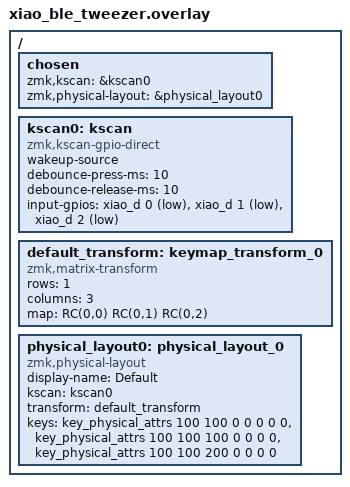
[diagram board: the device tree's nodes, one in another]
/*
 * SPDX-License-Identifier: MIT
 */

#include <dt-bindings/zmk/matrix_transform.h>
#include <physical_layouts.dtsi>
#include <zephyr/dt-bindings/gpio/gpio.h>

/ {
    chosen {
        zmk,kscan = &kscan0;
        zmk,physical-layout = &physical_layout0;
    };

    kscan0: kscan {
        compatible = "zmk,kscan-gpio-direct";
        wakeup-source;
        debounce-press-ms = <10>;
        debounce-release-ms = <10>;
        input-gpios
            = <&xiao_d 0 (GPIO_ACTIVE_LOW | GPIO_PULL_UP)>
            , <&xiao_d 1 (GPIO_ACTIVE_LOW | GPIO_PULL_UP)>
            , <&xiao_d 2 (GPIO_ACTIVE_LOW | GPIO_PULL_UP)>
            ;
    };

    default_transform: keymap_transform_0 {
        compatible = "zmk,matrix-transform";
        rows = <1>;
        columns = <3>;
        map = <RC(0,0) RC(0,1) RC(0,2)>;
    };

    physical_layout0: physical_layout_0 {
        compatible = "zmk,physical-layout";
        display-name = "Default";
        kscan = <&kscan0>;
        transform = <&default_transform>;
        keys
            = <&key_physical_attrs 100 100   0 0 0 0 0>
            , <&key_physical_attrs 100 100 100 0 0 0 0>
            , <&key_physical_attrs 100 100 200 0 0 0 0>
            ;
    };
};
